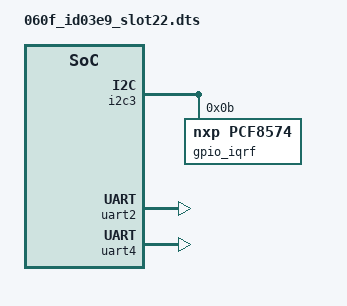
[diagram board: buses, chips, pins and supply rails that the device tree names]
/dts-v1/;


/plugin/;

/ {
	fragment@0 {
		target = <&i2c3>;
		__overlay__ {
			#address-cells = <1>;
			#size-cells = <0>;
			gpio_iqrf: pca9501@11 {
				compatible = "nxp,pcf8574";
				gpio-controller;
				#gpio-cells = <2>;
				reg = <11>;
                lines-initial-states = <0xFF>;
				gpio-line-names = "",
					"",
					"",
					"SLOT22_EXT_DI1",
					"SLOT22_EXT_DI2",
					"SLOT22_BUTTON1",
					"SLOT22_BUTTON2",
					"SLOT22_ESP32_EN";
			};
		};
	};

	fragment@2 {
		
		target = <&uart2>;
		__overlay__ {
			status = "okay";
		};

	};

	fragment@3 {
		
		target = <&uart4>;
		__overlay__ {
			status = "okay";
		};

	};
};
